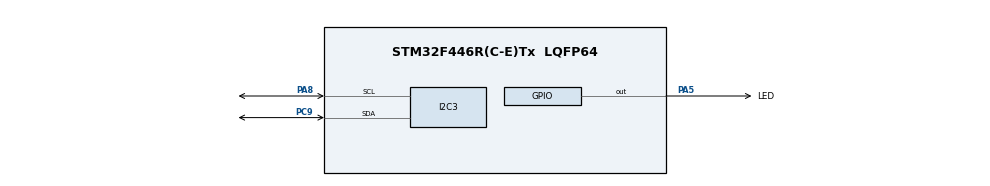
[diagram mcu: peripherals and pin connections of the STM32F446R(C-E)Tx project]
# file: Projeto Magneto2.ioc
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Mcu.Family=STM32F4
RCC.VCOOutputFreq_Value=192000000
RCC.CortexFreq_Value=16000000
PC9.Mode=I2C
PA8.Signal=I2C3_SCL
Mcu.Name=STM32F446R(C-E)Tx
Mcu.Package=LQFP64
ProjectManager.StackSize=0x400
PA5.GPIO_Label=LED
ProjectManager.HeapSize=0x200
ProjectManager.TargetToolchain=STM32CubeIDE
NVIC.PriorityGroup=NVIC_PRIORITYGROUP_4
PA8.Mode=I2C
PC9.Signal=I2C3_SDA
RCC.USBFreq_Value=96000000
PA5.Signal=GPIO_Output
board=custom

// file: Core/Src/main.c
/* USER CODE BEGIN Header */
/**
  ******************************************************************************
  * @file           : main.c
  * @brief          : Main program body
  ******************************************************************************
  * @attention
  *
  * <h2><center>&copy; Copyright (c) 2023 STMicroelectronics.
  * All rights reserved.</center></h2>
  *
  * This software component is licensed by ST under BSD 3-Clause license,
  * the "License"; You may not use this file except in compliance with the
  * License. You may obtain a copy of the License at:
  *                        opensource.org/licenses/BSD-3-Clause
  *
  ******************************************************************************
  */
/* USER CODE END Header */
#include "main.h"

/* USER CODE BEGIN Includes */
#include "MAGNETOMETRO.h"
/* USER CODE END Includes */

I2C_HandleTypeDef hi2c3;

/* USER CODE BEGIN PV */
uint16_t angulo;

/* USER CODE END PV */

void SystemClock_Config(void);
static void MX_GPIO_Init(void);
static void MX_I2C3_Init(void);

int main(void)
{

  /* MCU Configuration--------------------------------------------------------*/

  /* Reset of all peripherals, Initializes the Flash interface and the Systick. */
  HAL_Init();

  /* Configure the system clock */
  SystemClock_Config();

  /* Initialize all configured peripherals */
  MX_GPIO_Init();
  MX_I2C3_Init();
  /* USER CODE BEGIN 2 */

  // Exemplode configuração do ganho, taxa de aquisição e modo de operação do magnetômetro
  uint8_t config[3] = {0x70, 0xA0, 0x00}; // Valores de exemplo para CONTROL REG A, CONTROL REG B e MODE REGISTER
  // config[0] = 0x70 = 01110000 -> Configuração de medição normal, output de dados de 15 Hz e média de 8 amostras por medição
  // config[1] = 0xA0 = 10100000 -> Ganho de 4.7 GA
  // config[2] = 0x00 = 00000000 -> Modo de leitura contínua
  configuraMagnetometro(hi2c3, config[0], config[1], config[2]);
  /* USER CODE END 2 */

  /* Infinite loop */
  while (1)
  {

    /* USER CODE BEGIN 3 */
	 angulo = (uint16_t) getAngulo(hi2c3);
  }
  /* USER CODE END 3 */
}

void SystemClock_Config(void)
{
  RCC_OscInitTypeDef RCC_OscInitStruct = {0};
  RCC_ClkInitTypeDef RCC_ClkInitStruct = {0};

  /** Configure the main internal regulator output voltage
  */
  __HAL_RCC_PWR_CLK_ENABLE();
  __HAL_PWR_VOLTAGESCALING_CONFIG(PWR_REGULATOR_VOLTAGE_SCALE3);
  /** Initializes the RCC Oscillators according to the specified parameters
  * in the RCC_OscInitTypeDef structure.
  */
  RCC_OscInitStruct.OscillatorType = RCC_OSCILLATORTYPE_HSI;
  RCC_OscInitStruct.HSIState = RCC_HSI_ON;
  RCC_OscInitStruct.HSICalibrationValue = RCC_HSICALIBRATION_DEFAULT;
  RCC_OscInitStruct.PLL.PLLState = RCC_PLL_NONE;
  if (HAL_RCC_OscConfig(&RCC_OscInitStruct) != HAL_OK)
  {
    Error_Handler();
  }
  /** Initializes the CPU, AHB and APB buses clocks
  */
  RCC_ClkInitStruct.ClockType = RCC_CLOCKTYPE_HCLK|RCC_CLOCKTYPE_SYSCLK
                              |RCC_CLOCKTYPE_PCLK1|RCC_CLOCKTYPE_PCLK2;
  RCC_ClkInitStruct.SYSCLKSource = RCC_SYSCLKSOURCE_HSI;
  RCC_ClkInitStruct.AHBCLKDivider = RCC_SYSCLK_DIV1;
  RCC_ClkInitStruct.APB1CLKDivider = RCC_HCLK_DIV1;
  RCC_ClkInitStruct.APB2CLKDivider = RCC_HCLK_DIV1;

  if (HAL_RCC_ClockConfig(&RCC_ClkInitStruct, FLASH_LATENCY_0) != HAL_OK)
  {
    Error_Handler();
  }
}

static void MX_I2C3_Init(void)
{

  hi2c3.Instance = I2C3;
  hi2c3.Init.ClockSpeed = 100000;
  hi2c3.Init.DutyCycle = I2C_DUTYCYCLE_2;
  hi2c3.Init.OwnAddress1 = 0;
  hi2c3.Init.AddressingMode = I2C_ADDRESSINGMODE_7BIT;
  hi2c3.Init.DualAddressMode = I2C_DUALADDRESS_DISABLE;
  hi2c3.Init.OwnAddress2 = 0;
  hi2c3.Init.GeneralCallMode = I2C_GENERALCALL_DISABLE;
  hi2c3.Init.NoStretchMode = I2C_NOSTRETCH_DISABLE;
  if (HAL_I2C_Init(&hi2c3) != HAL_OK)
  {
    Error_Handler();
  }

}

static void MX_GPIO_Init(void)
{
  GPIO_InitTypeDef GPIO_InitStruct = {0};

  /* GPIO Ports Clock Enable */
  __HAL_RCC_GPIOA_CLK_ENABLE();
  __HAL_RCC_GPIOC_CLK_ENABLE();

  /*Configure GPIO pin Output Level */
  HAL_GPIO_WritePin(LED_GPIO_Port, LED_Pin, GPIO_PIN_RESET);

  /*Configure GPIO pin : LED_Pin */
  GPIO_InitStruct.Pin = LED_Pin;
  GPIO_InitStruct.Mode = GPIO_MODE_OUTPUT_PP;
  GPIO_InitStruct.Pull = GPIO_NOPULL;
  GPIO_InitStruct.Speed = GPIO_SPEED_FREQ_LOW;
  HAL_GPIO_Init(LED_GPIO_Port, &GPIO_InitStruct);

}

void Error_Handler(void)
{
  __disable_irq();
  while (1)
  {
  }
}

/************************ (C) COPYRIGHT STMicroelectronics *****END OF FILE****/
